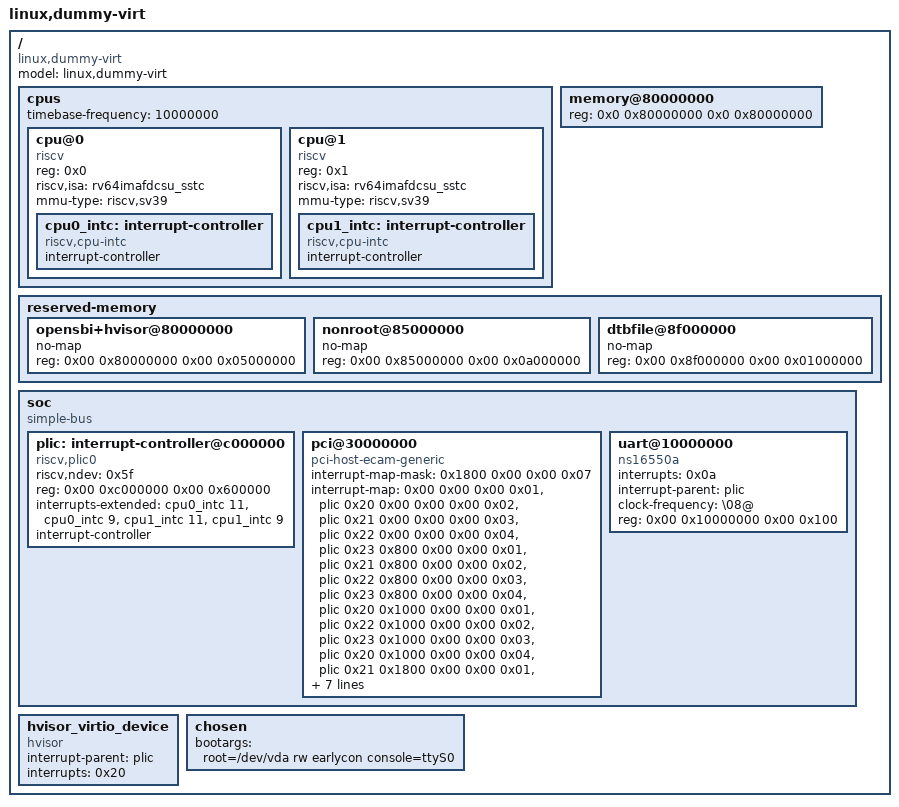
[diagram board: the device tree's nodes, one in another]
/dts-v1/;

/ {
	#address-cells = <0x2>;
	#size-cells = <0x2>;
	model = "linux,dummy-virt";
	compatible = "linux,dummy-virt";

	cpus {
		#address-cells = <0x1>;
		#size-cells = <0x0>;
		timebase-frequency = <10000000>;

		cpu@0 {
			device_type = "cpu";
			reg = <0x0>;
			status = "okay";
			compatible = "riscv";
			riscv,isa = "rv64imafdcsu_sstc";
			mmu-type = "riscv,sv39";

			cpu0_intc: interrupt-controller {
				#interrupt-cells = <0x1>;
				interrupt-controller;
				compatible = "riscv,cpu-intc";
			};
		};

		cpu@1 {
			device_type = "cpu";
			reg = <0x1>;
			status = "okay";
			compatible = "riscv";
			riscv,isa = "rv64imafdcsu_sstc";
			mmu-type = "riscv,sv39";

			cpu1_intc: interrupt-controller {
				#interrupt-cells = <0x1>;
				interrupt-controller;
				compatible = "riscv,cpu-intc";
			};
		};
	};

	memory@80000000 {
		device_type = "memory";
		reg = <0x0 0x80000000 0x0 0x80000000>;
	};

	reserved-memory {
		#address-cells = <0x02>;
		#size-cells = <0x02>;
		ranges;

		opensbi+hvisor@80000000 {   // reserved for opensbi and hvisor
			no-map;
			reg = <0x00 0x80000000 0x00 0x05000000>;
		};

		nonroot@85000000 {
			no-map;
			reg = <0x00 0x85000000 0x00 0x0a000000>;
		};

		dtbfile@8f000000 {
			no-map;
			reg = <0x00 0x8f000000 0x00 0x01000000>;
		};
	};

	soc {
		#address-cells = <0x02>;
		#size-cells = <0x02>;
		compatible = "simple-bus";
		ranges;
		
		plic: interrupt-controller@c000000 {
			phandle = <0x03>;
			riscv,ndev = <0x5f>;
			reg = <0x00 0xc000000 0x00 0x600000>;
			interrupts-extended = <&cpu0_intc 11 &cpu0_intc 9 &cpu1_intc 11 &cpu1_intc 9>;
			interrupt-controller;
			compatible = "riscv,plic0";
			#interrupt-cells = <0x1>;
		};

		pci@30000000 {
			interrupt-map-mask = <0x1800 0x00 0x00 0x07>;
			interrupt-map = <0x00 0x00 0x00 0x01 &plic 0x20
			0x00 0x00 0x00 0x02 &plic 0x21
			0x00 0x00 0x00 0x03 &plic 0x22
			0x00 0x00 0x00 0x04 &plic 0x23 
			0x800 0x00 0x00 0x01 &plic 0x21
			0x800 0x00 0x00 0x02 &plic 0x22
			0x800 0x00 0x00 0x03 &plic 0x23
			0x800 0x00 0x00 0x04 &plic 0x20
			0x1000 0x00 0x00 0x01 &plic 0x22
			0x1000 0x00 0x00 0x02 &plic 0x23
			0x1000 0x00 0x00 0x03 &plic 0x20
			0x1000 0x00 0x00 0x04 &plic 0x21
			0x1800 0x00 0x00 0x01 &plic 0x23
			0x1800 0x00 0x00 0x02 &plic 0x20
			0x1800 0x00 0x00 0x03 &plic 0x21
			0x1800 0x00 0x00 0x04 &plic 0x22>;
			ranges = <0x1000000 0x00 0x00 0x00 0x3000000 0x00 0x10000
			0x2000000 0x00 0x40000000 0x00 0x40000000 0x00 0x40000000
			0x3000000 0x04 0x00 0x04 0x00 0x04 0x00>;
			reg = <0x00 0x30000000 0x00 0x10000000>;
			dma-coherent;
			bus-range = <0x00 0xff>;
			linux,pci-domain = <0x00>;
			device_type = "pci";
			compatible = "pci-host-ecam-generic";
			#size-cells = <0x02>;
			#interrupt-cells = <0x01>;
			#address-cells = <0x03>;
		};

		uart@10000000 {
			interrupts = <0x0a>;
			interrupt-parent = <&plic>;
			clock-frequency = "\08@";
			reg = <0x00 0x10000000 0x00 0x100>;
			compatible = "ns16550a";
		};
	};

	hvisor_virtio_device {
		compatible = "hvisor";
		interrupt-parent = <&plic>;
		interrupts = <0x20>;
	};

	chosen {
		bootargs = "root=/dev/vda rw earlycon console=ttyS0";
	};
};
